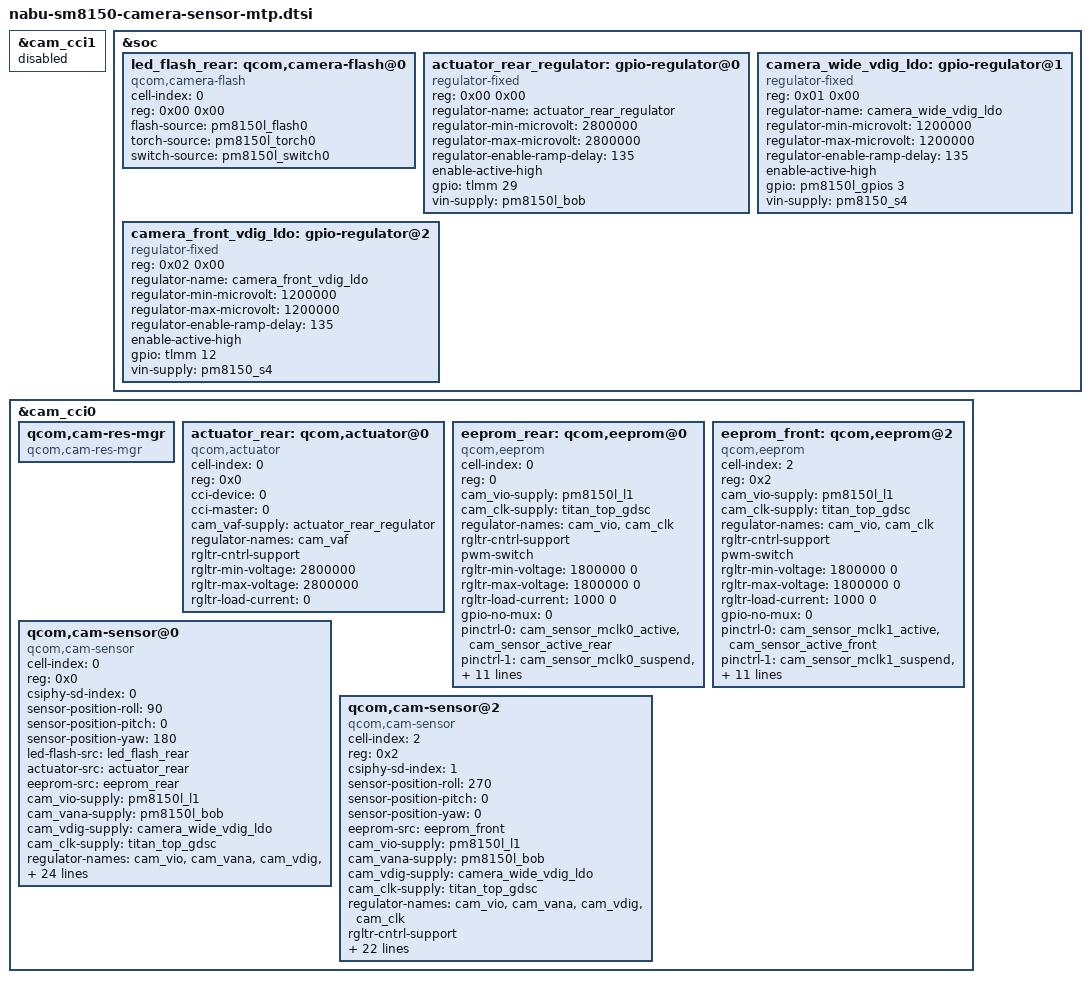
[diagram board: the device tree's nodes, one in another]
/*
 * Copyright (c) 2018, The Linux Foundation. All rights reserved.
 * Copyright (C) 2021 XiaoMi, Inc.
 *
 * This program is free software; you can redistribute it and/or modify
 * it under the terms of the GNU General Public License version 2 and
 * only version 2 as published by the Free Software Foundation.
 *
 * This program is distributed in the hope that it will be useful,
 * but WITHOUT ANY WARRANTY; without even the implied warranty of
 * MERCHANTABILITY or FITNESS FOR A PARTICULAR PURPOSE.  See the
 * GNU General Public License for more details.
 */
&cam_cci1 {
	status = "disable";
};

&soc {
	led_flash_rear: qcom,camera-flash@0 {
		cell-index = <0>;
		reg = <0x00 0x00>;
		compatible = "qcom,camera-flash";
		flash-source = <&pm8150l_flash0>;
		torch-source = <&pm8150l_torch0>;
		switch-source = <&pm8150l_switch0>;
		status = "ok";
	};

	actuator_rear_regulator: gpio-regulator@0 {
		compatible = "regulator-fixed";
		reg = <0x00 0x00>;
		regulator-name = "actuator_rear_regulator";
		regulator-min-microvolt = <2800000>;
		regulator-max-microvolt = <2800000>;
		regulator-enable-ramp-delay = <135>;
		enable-active-high;
		gpio = <&tlmm 29 0>;
		vin-supply = <&pm8150l_bob>;
	};

	camera_wide_vdig_ldo: gpio-regulator@1 {
		compatible = "regulator-fixed";
		reg = <0x01 0x00>;
		regulator-name = "camera_wide_vdig_ldo";
		regulator-min-microvolt = <1200000>;
		regulator-max-microvolt = <1200000>;
		regulator-enable-ramp-delay = <135>;
		enable-active-high;
		gpio = <&pm8150l_gpios 3 0>;
		vin-supply = <&pm8150_s4>;
	};

	camera_front_vdig_ldo: gpio-regulator@2 {
		compatible = "regulator-fixed";
		reg = <0x02 0x00>;
		regulator-name = "camera_front_vdig_ldo";
		regulator-min-microvolt = <1200000>;
		regulator-max-microvolt = <1200000>;
		regulator-enable-ramp-delay = <135>;
		enable-active-high;
		gpio = <&tlmm 12 0>;
		vin-supply = <&pm8150_s4>;
	};
};

&cam_cci0 {
	qcom,cam-res-mgr {
		compatible = "qcom,cam-res-mgr";
		status = "ok";
	};

	actuator_rear: qcom,actuator@0 {
		cell-index = <0>;
		reg = <0x0>;
		compatible = "qcom,actuator";
		cci-device = <0>;
		cci-master = <0>;
		cam_vaf-supply = <&actuator_rear_regulator>;
		regulator-names = "cam_vaf";
		rgltr-cntrl-support;
		rgltr-min-voltage = <2800000>;
		rgltr-max-voltage = <2800000>;
		rgltr-load-current = <0>;
	};

	eeprom_rear: qcom,eeprom@0 {
		cell-index = <0>;
		reg = <0>;
		compatible = "qcom,eeprom";
		cam_vio-supply = <&pm8150l_l1>;
		cam_clk-supply = <&titan_top_gdsc>;
		regulator-names = "cam_vio","cam_clk";
		rgltr-cntrl-support;
		pwm-switch;
		rgltr-min-voltage = <1800000 0>;
		rgltr-max-voltage = <1800000 0>;
		rgltr-load-current = <1000 0>;
		gpio-no-mux = <0>;
		pinctrl-names = "cam_default", "cam_suspend";
		pinctrl-0 = <&cam_sensor_mclk0_active
						&cam_sensor_active_rear>;
		pinctrl-1 = <&cam_sensor_mclk0_suspend
						&cam_sensor_suspend_rear>;
		gpios = <&tlmm 13 0>;
		gpio-req-tbl-num = <0>;
		gpio-req-tbl-flags = <1>;
		gpio-req-tbl-label = "CAMIF_MCLK0";
		sensor-mode = <0>;
		cci-device = <0>;
		cci-master = <0>;
		status = "ok";
		clocks = <&clock_camcc CAM_CC_MCLK0_CLK>;
		clock-names = "cam_clk";
		clock-cntl-level = "turbo";
		clock-rates = <19200000>;
	};

	eeprom_front: qcom,eeprom@2 {
		cell-index = <2>;
		reg = <0x2>;
		compatible = "qcom,eeprom";
		cam_vio-supply = <&pm8150l_l1>;
		cam_clk-supply = <&titan_top_gdsc>;
		regulator-names = "cam_vio","cam_clk";
		rgltr-cntrl-support;
		pwm-switch;
		rgltr-min-voltage = <1800000 0>;
		rgltr-max-voltage = <1800000 0>;
		rgltr-load-current = <1000 0>;
		gpio-no-mux = <0>;
		pinctrl-names = "cam_default", "cam_suspend";
		pinctrl-0 = <&cam_sensor_mclk1_active
						&cam_sensor_active_front>;
		pinctrl-1 = <&cam_sensor_mclk1_suspend
						&cam_sensor_suspend_front>;
		gpios = <&tlmm 14 0>;
		gpio-req-tbl-num = <0>;
		gpio-req-tbl-flags = <1>;
		gpio-req-tbl-label = "CAMIF_MCLK2";
		sensor-mode = <0>;
		cci-device = <0>;
		cci-master = <1>;
		status = "ok";
		clocks = <&clock_camcc CAM_CC_MCLK1_CLK>;
		clock-names = "cam_clk";
		clock-cntl-level = "turbo";
		clock-rates = <19200000>;
	};

	//ov13b10
	qcom,cam-sensor@0 {
		cell-index = <0>;
		compatible = "qcom,cam-sensor";
		reg = <0x0>;
		csiphy-sd-index = <0>;
		sensor-position-roll = <90>;
		sensor-position-pitch = <0>;
		sensor-position-yaw = <180>;
		led-flash-src = <&led_flash_rear>;
		actuator-src = <&actuator_rear>;
		eeprom-src = <&eeprom_rear>;
		cam_vio-supply = <&pm8150l_l1>;
		cam_vana-supply = <&pm8150l_bob>;
		cam_vdig-supply = <&camera_wide_vdig_ldo>;
		cam_clk-supply = <&titan_top_gdsc>;
		regulator-names = "cam_vio", "cam_vana","cam_vdig", "cam_clk";
		rgltr-cntrl-support;
		pwm-switch;
		rgltr-min-voltage = <1800000 3008000 1200000 0>;
		rgltr-max-voltage = <1800000 4000000 1200000 0>;
		rgltr-load-current = <180000 2000000 100000 0>;
		gpio-no-mux = <0>;
		pinctrl-names = "cam_default", "cam_suspend";
		pinctrl-0 = <&cam_sensor_mclk0_active
				&cam_sensor_active_rear>;
		pinctrl-1 = <&cam_sensor_mclk0_suspend
				&cam_sensor_suspend_rear>;
		gpios = <&tlmm 13 0>,
			<&tlmm 28 0>,
			<&tlmm 11 0>;
		gpio-reset = <1>;
		gpio-vana = <2>;
		gpio-req-tbl-num = <0 1 2>;
		gpio-req-tbl-flags = <1 0 0>;
		gpio-req-tbl-label = "CAMIF_MCLK0",
					"CAM_RESET0",
					"CAM_VANA0";
		sensor-mode = <0>;
		cci-device = <0>;
		cci-master = <0>;
		status = "ok";
		clocks = <&clock_camcc CAM_CC_MCLK0_CLK>;
		clock-names = "cam_clk";
		clock-cntl-level = "turbo";
		clock-rates = <19200000>;
	};

	//ov8856
	qcom,cam-sensor@2 {
		cell-index = <2>;
		compatible = "qcom,cam-sensor";
		reg = <0x2>;
		csiphy-sd-index = <1>;
		sensor-position-roll = <270>;
		sensor-position-pitch = <0>;
		sensor-position-yaw = <0>;
		eeprom-src = <&eeprom_front>;
		cam_vio-supply = <&pm8150l_l1>;
		cam_vana-supply = <&pm8150l_bob>;
		cam_vdig-supply = <&camera_wide_vdig_ldo>;
		cam_clk-supply = <&titan_top_gdsc>;
		regulator-names = "cam_vio", "cam_vana", "cam_vdig", "cam_clk";
		rgltr-cntrl-support;
		pwm-switch;
		rgltr-min-voltage = <1800000 3008000 1200000 0>;
		rgltr-max-voltage = <1800000 4000000 1200000 0>;
		rgltr-load-current = <180000 2000000 100000 0>;
		gpio-no-mux = <0>;
		pinctrl-names = "cam_default", "cam_suspend";
		pinctrl-0 = <&cam_sensor_mclk1_active
				&cam_sensor_active_front>;
		pinctrl-1 = <&cam_sensor_mclk1_suspend
				&cam_sensor_suspend_front>;
		gpios = <&tlmm 14 0>,
			<&tlmm 30 0>,
			<&tlmm 31 0>;
		gpio-reset = <1>;
		gpio-vana = <2>;
		gpio-req-tbl-num = <0 1 2>;
		gpio-req-tbl-flags = <1 0 0>;
		gpio-req-tbl-label = "CAMIF_MCLK2",
					"CAM_RESET2",
					"CAM_VANA2";
		sensor-mode = <0>;
		cci-device = <0>;
		cci-master = <1>;
		status = "ok";
		clocks = <&clock_camcc CAM_CC_MCLK1_CLK>;
		clock-names = "cam_clk";
		clock-cntl-level = "turbo";
		clock-rates = <19200000>;
	};
};

